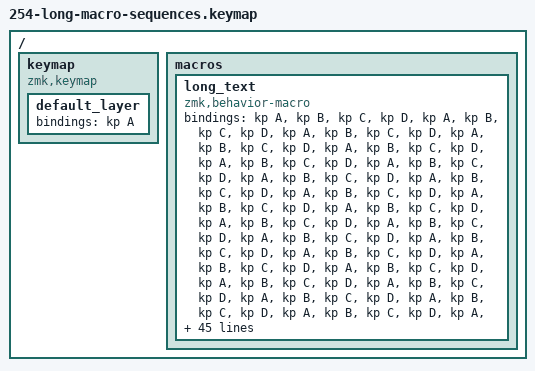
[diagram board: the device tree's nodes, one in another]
/* Synthesized: issue #254 concerns preprocessor/comment handling and contains no long sequence excerpt. */
/ {
    keymap {
        compatible = "zmk,keymap";
        default_layer { bindings = <&kp A>; };
    };

    macros { long_text: long_text { compatible = "zmk,behavior-macro"; #binding-cells = <0>; bindings = <&kp A &kp B &kp C &kp D &kp A &kp B &kp C &kp D &kp A &kp B &kp C &kp D &kp A &kp B &kp C &kp D &kp A &kp B &kp C &kp D &kp A &kp B &kp C &kp D &kp A &kp B &kp C &kp D &kp A &kp B &kp C &kp D &kp A &kp B &kp C &kp D &kp A &kp B &kp C &kp D &kp A &kp B &kp C &kp D &kp A &kp B &kp C &kp D &kp A &kp B &kp C &kp D &kp A &kp B &kp C &kp D &kp A &kp B &kp C &kp D &kp A &kp B &kp C &kp D &kp A &kp B &kp C &kp D &kp A &kp B &kp C &kp D &kp A &kp B &kp C &kp D &kp A &kp B &kp C &kp D &kp A &kp B &kp C &kp D &kp A &kp B &kp C &kp D &kp A &kp B &kp C &kp D &kp A &kp B &kp C &kp D &kp A &kp B &kp C &kp D &kp A &kp B &kp C &kp D &kp A &kp B &kp C &kp D &kp A &kp B &kp C &kp D &kp A &kp B &kp C &kp D &kp A &kp B &kp C &kp D &kp A &kp B &kp C &kp D &kp A &kp B &kp C &kp D &kp A &kp B &kp C &kp D &kp A &kp B &kp C &kp D &kp A &kp B &kp C &kp D &kp A &kp B &kp C &kp D &kp A &kp B &kp C &kp D &kp A &kp B &kp C &kp D &kp A &kp B &kp C &kp D &kp A &kp B &kp C &kp D &kp A &kp B &kp C &kp D &kp A &kp B &kp C &kp D &kp A &kp B &kp C &kp D &kp A &kp B &kp C &kp D &kp A &kp B &kp C &kp D &kp A &kp B &kp C &kp D &kp A &kp B &kp C &kp D &kp A &kp B &kp C &kp D &kp A &kp B &kp C &kp D &kp A &kp B &kp C &kp D &kp A &kp B &kp C &kp D &kp A &kp B &kp C &kp D &kp A &kp B &kp C &kp D &kp A &kp B &kp C &kp D &kp A &kp B &kp C &kp D &kp A &kp B &kp C &kp D &kp A &kp B &kp C &kp D &kp A &kp B &kp C &kp D &kp A &kp B &kp C &kp D &kp A &kp B &kp C &kp D &kp A &kp B &kp C &kp D &kp A &kp B &kp C &kp D &kp A &kp B &kp C &kp D &kp A &kp B &kp C &kp D &kp A &kp B &kp C &kp D &kp A &kp B &kp C &kp D &kp A &kp B &kp C &kp D &kp A &kp B &kp C &kp D &kp A &kp B &kp C &kp D &kp A &kp B &kp C &kp D &kp A &kp B &kp C &kp D &kp A &kp B &kp C &kp D &kp A &kp B &kp C &kp D &kp A &kp B &kp C &kp D &kp A &kp B &kp C &kp D &kp A &kp B &kp C &kp D &kp A &kp B &kp C &kp D &kp A &kp B &kp C &kp D &kp A &kp B &kp C &kp D &kp A &kp B &kp C &kp D &kp A &kp B &kp C &kp D &kp A &kp B &kp C &kp D &kp A &kp B &kp C &kp D &kp A &kp B &kp C &kp D &kp A &kp B &kp C &kp D &kp A &kp B &kp C &kp D &kp A &kp B &kp C &kp D &kp A &kp B &kp C &kp D &kp A &kp B &kp C &kp D &kp A &kp B &kp C &kp D &kp A &kp B &kp C &kp D &kp A &kp B &kp C &kp D &kp A &kp B &kp C &kp D &kp A &kp B &kp C &kp D &kp A &kp B &kp C &kp D &kp A &kp B &kp C &kp D &kp A &kp B &kp C &kp D &kp A &kp B &kp C &kp D &kp A &kp B &kp C &kp D &kp A &kp B &kp C &kp D>; label = "LONG_TEXT"; }; };
};
